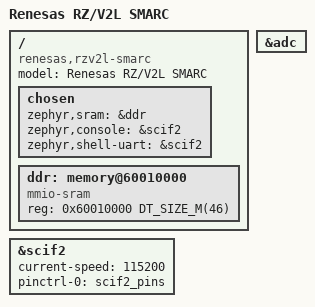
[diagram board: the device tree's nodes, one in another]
/*
 * Copyright (c) 2025 Renesas Electronics Corporation
 * SPDX-License-Identifier: Apache-2.0
 */

/dts-v1/;

#include <zephyr/dt-bindings/memory-attr/memory-attr-arm.h>
#include <zephyr/dt-bindings/input/input-event-codes.h>
#include <zephyr/dt-bindings/gpio/renesas-rz-gpio.h>
#include <arm/renesas/rz/rzv/r9a07g054.dtsi>
#include "rzv2l_smarc-pinctrl.dtsi"

/ {
	model = "Renesas RZ/V2L SMARC";
	compatible = "renesas,rzv2l-smarc";

	chosen {
		zephyr,sram = &ddr;
		zephyr,console = &scif2;
		zephyr,shell-uart = &scif2;
	};

	ddr: memory@60010000 {
		compatible = "mmio-sram";
		reg = <0x60010000 DT_SIZE_M(46)>;
	};
};

&scif2 {
	current-speed = <115200>;
	pinctrl-0 = <&scif2_pins>;
	pinctrl-names = "default";
	status = "okay";
};

&adc {
	status = "okay";
};
